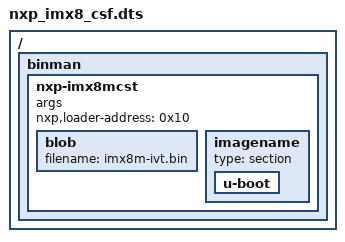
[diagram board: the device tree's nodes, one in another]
// SPDX-License-Identifier: GPL-2.0+

/dts-v1/;

/ {
	#address-cells = <1>;
	#size-cells = <1>;

	binman {
		nxp-imx8mcst {
			args;
			nxp,loader-address = <0x10>;

			blob {
				filename = "imx8m-ivt.bin";
			};

			imagename {
				type = "section";

				u-boot {
				};
			};
		};
	};
};
